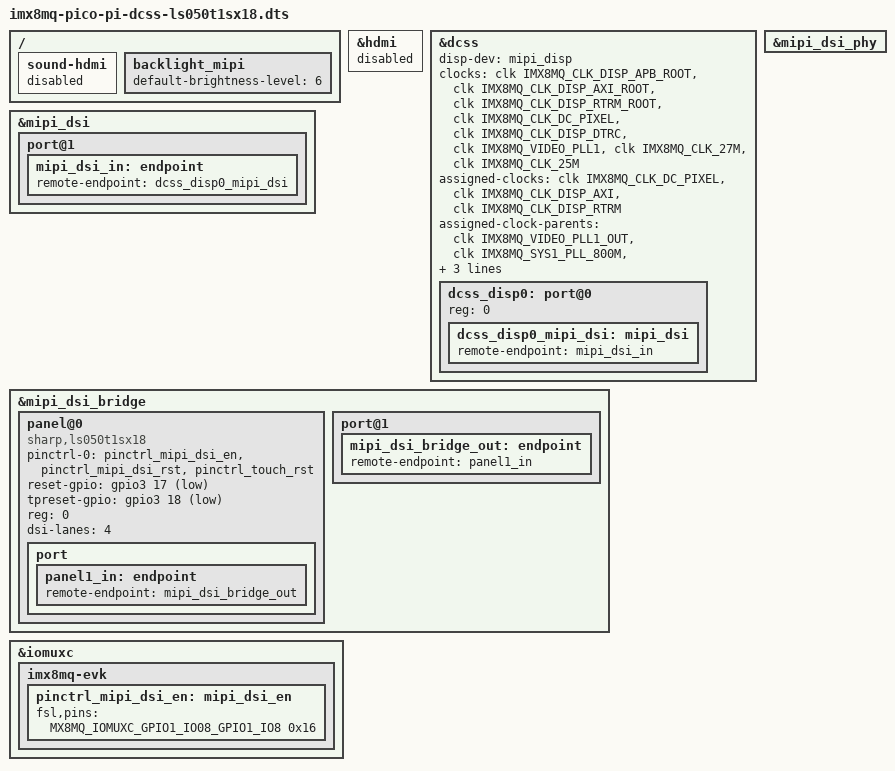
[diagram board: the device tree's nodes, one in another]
/*
 * Copyright 2019 PCS
 *
 * Author: Linh Nguyen <nvl1109@gmail.com>
 */

/dts-v1/;

#include "imx8mq-pico-pi.dts"

/ {
	sound-hdmi {
		status = "disabled";
	};

	/* PCS was fixed the brightness level, so just enable it */
	backlight_mipi {
		status = "okay";
		default-brightness-level = <6>;
	};
};

&hdmi {
	status = "disabled";
};

&dcss {
	status = "okay";
	disp-dev = "mipi_disp";

	clocks = <&clk IMX8MQ_CLK_DISP_APB_ROOT>,
		 <&clk IMX8MQ_CLK_DISP_AXI_ROOT>,
		 <&clk IMX8MQ_CLK_DISP_RTRM_ROOT>,
		 <&clk IMX8MQ_CLK_DC_PIXEL>,
		 <&clk IMX8MQ_CLK_DISP_DTRC>,
		 <&clk IMX8MQ_VIDEO_PLL1>,
		 <&clk IMX8MQ_CLK_27M>,
		 <&clk IMX8MQ_CLK_25M>;
	clock-names = "apb", "axi", "rtrm", "pix", "dtrc", "pll",
		      "pll_src1", "pll_src2";

	assigned-clocks = <&clk IMX8MQ_CLK_DC_PIXEL>,
			  <&clk IMX8MQ_CLK_DISP_AXI>,
			  <&clk IMX8MQ_CLK_DISP_RTRM>;
	assigned-clock-parents = <&clk IMX8MQ_VIDEO_PLL1_OUT>,
				 <&clk IMX8MQ_SYS1_PLL_800M>,
				 <&clk IMX8MQ_SYS1_PLL_800M>;
	assigned-clock-rates = <600000000>,
			       <800000000>,
			       <400000000>;

	dcss_disp0: port@0 {
		reg = <0>;

		dcss_disp0_mipi_dsi: mipi_dsi {
			remote-endpoint = <&mipi_dsi_in>;
		};
	};
};

&mipi_dsi_phy {
	status = "okay";
};

&mipi_dsi {
	status = "okay";

	port@1 {
		mipi_dsi_in: endpoint {
			remote-endpoint = <&dcss_disp0_mipi_dsi>;
		};
	};

};

&mipi_dsi_bridge {
	status = "okay";

	panel@0 {
		compatible = "sharp,ls050t1sx18";
		pinctrl-0 = <&pinctrl_mipi_dsi_en &pinctrl_mipi_dsi_rst &pinctrl_touch_rst>;
		reset-gpio = <&gpio3 17 GPIO_ACTIVE_LOW>;
		tpreset-gpio = <&gpio3 18 GPIO_ACTIVE_LOW>;
		reg = <0>;
		dsi-lanes = <4>;

		port {
			panel1_in: endpoint {
				remote-endpoint = <&mipi_dsi_bridge_out>;
			};
		};
	};

	port@1 {
		mipi_dsi_bridge_out: endpoint {
			remote-endpoint = <&panel1_in>;
		};
	};
};

&iomuxc {
	imx8mq-evk {
		pinctrl_mipi_dsi_en: mipi_dsi_en {
			fsl,pins = <
				MX8MQ_IOMUXC_GPIO1_IO08_GPIO1_IO8	0x16
			>;
		};

	};
};
